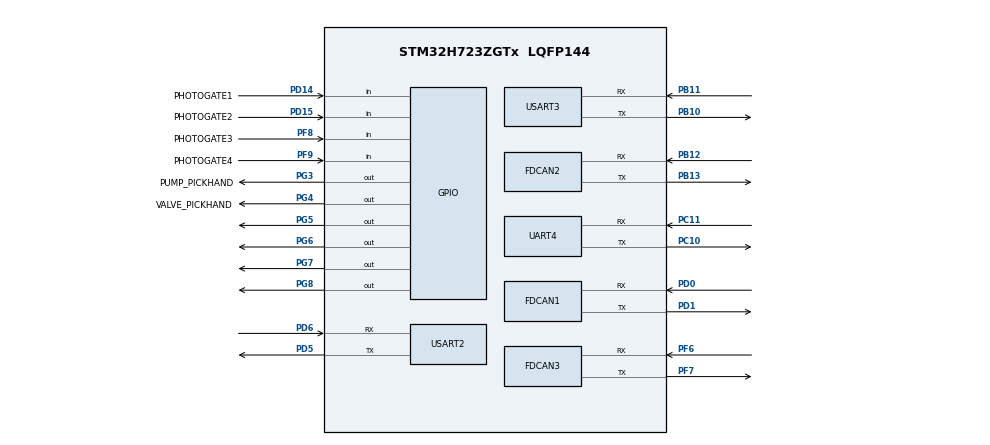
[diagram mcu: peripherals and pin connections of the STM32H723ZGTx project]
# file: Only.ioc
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CORTEX_M7.default_mode_Activation=1
Dma.Request0=USART3_TX
Dma.Request1=USART3_RX
Dma.Request2=USART2_RX
Dma.Request3=USART2_TX
Dma.Request4=UART4_RX
Dma.Request5=UART4_TX
Dma.UART4_RX.4.Direction=DMA_PERIPH_TO_MEMORY
Dma.UART4_RX.4.EventEnable=DISABLE
Dma.UART4_RX.4.FIFOMode=DMA_FIFOMODE_DISABLE
Dma.UART4_RX.4.Instance=DMA1_Stream4
Dma.UART4_RX.4.MemDataAlignment=DMA_MDATAALIGN_BYTE
Dma.UART4_RX.4.MemInc=DMA_MINC_ENABLE
Dma.UART4_RX.4.Mode=DMA_CIRCULAR
Dma.UART4_RX.4.PeriphDataAlignment=DMA_PDATAALIGN_BYTE
Dma.UART4_RX.4.PeriphInc=DMA_PINC_DISABLE
Dma.UART4_RX.4.Polarity=HAL_DMAMUX_REQ_GEN_RISING
Dma.UART4_RX.4.Priority=DMA_PRIORITY_LOW
Dma.UART4_RX.4.RequestNumber=1
Dma.UART4_RX.4.SignalID=NONE
Dma.UART4_RX.4.SyncEnable=DISABLE
Dma.UART4_RX.4.SyncPolarity=HAL_DMAMUX_SYNC_NO_EVENT
Dma.UART4_RX.4.SyncRequestNumber=1
Dma.UART4_RX.4.SyncSignalID=NONE
Dma.UART4_TX.5.Direction=DMA_MEMORY_TO_PERIPH
Dma.UART4_TX.5.EventEnable=DISABLE
Dma.UART4_TX.5.FIFOMode=DMA_FIFOMODE_DISABLE
Dma.UART4_TX.5.Instance=DMA1_Stream5
Dma.UART4_TX.5.MemDataAlignment=DMA_MDATAALIGN_BYTE
Dma.UART4_TX.5.MemInc=DMA_MINC_ENABLE
Dma.UART4_TX.5.Mode=DMA_NORMAL
Dma.UART4_TX.5.PeriphDataAlignment=DMA_PDATAALIGN_BYTE
Dma.UART4_TX.5.PeriphInc=DMA_PINC_DISABLE
Dma.UART4_TX.5.Polarity=HAL_DMAMUX_REQ_GEN_RISING
Dma.UART4_TX.5.Priority=DMA_PRIORITY_LOW
Dma.UART4_TX.5.RequestNumber=1
Dma.UART4_TX.5.SignalID=NONE
Dma.UART4_TX.5.SyncEnable=DISABLE
Dma.UART4_TX.5.SyncPolarity=HAL_DMAMUX_SYNC_NO_EVENT
Dma.UART4_TX.5.SyncRequestNumber=1
Dma.UART4_TX.5.SyncSignalID=NONE
Dma.USART2_RX.2.Direction=DMA_PERIPH_TO_MEMORY
Dma.USART2_RX.2.EventEnable=DISABLE
Dma.USART2_RX.2.FIFOMode=DMA_FIFOMODE_DISABLE
Dma.USART2_RX.2.Instance=DMA1_Stream2
Dma.USART2_RX.2.MemDataAlignment=DMA_MDATAALIGN_BYTE
Dma.USART2_RX.2.MemInc=DMA_MINC_ENABLE
Dma.USART2_RX.2.Mode=DMA_CIRCULAR
Dma.USART2_RX.2.PeriphDataAlignment=DMA_PDATAALIGN_BYTE
Dma.USART2_RX.2.PeriphInc=DMA_PINC_DISABLE
Dma.USART2_RX.2.Polarity=HAL_DMAMUX_REQ_GEN_RISING
Dma.USART2_RX.2.Priority=DMA_PRIORITY_LOW
Dma.USART2_RX.2.RequestNumber=1
Dma.USART2_RX.2.SignalID=NONE
Dma.USART2_RX.2.SyncEnable=DISABLE
Dma.USART2_RX.2.SyncPolarity=HAL_DMAMUX_SYNC_NO_EVENT
Dma.USART2_RX.2.SyncRequestNumber=1
Dma.USART2_RX.2.SyncSignalID=NONE
Dma.USART2_TX.3.Direction=DMA_MEMORY_TO_PERIPH
Dma.USART2_TX.3.EventEnable=DISABLE
Dma.USART2_TX.3.FIFOMode=DMA_FIFOMODE_DISABLE
Dma.USART2_TX.3.Instance=DMA1_Stream3
Dma.USART2_TX.3.MemDataAlignment=DMA_MDATAALIGN_BYTE
Dma.USART2_TX.3.MemInc=DMA_MINC_ENABLE
Dma.USART2_TX.3.Mode=DMA_NORMAL
Dma.USART2_TX.3.PeriphDataAlignment=DMA_PDATAALIGN_BYTE
Dma.USART2_TX.3.PeriphInc=DMA_PINC_DISABLE
Dma.USART2_TX.3.Polarity=HAL_DMAMUX_REQ_GEN_RISING
Dma.USART2_TX.3.Priority=DMA_PRIORITY_LOW
Dma.USART2_TX.3.RequestNumber=1
Dma.USART2_TX.3.SignalID=NONE
Dma.USART2_TX.3.SyncEnable=DISABLE
Dma.USART2_TX.3.SyncPolarity=HAL_DMAMUX_SYNC_NO_EVENT
Dma.USART2_TX.3.SyncRequestNumber=1
Dma.USART2_TX.3.SyncSignalID=NONE
Dma.USART3_RX.1.Direction=DMA_PERIPH_TO_MEMORY
Dma.USART3_RX.1.EventEnable=DISABLE
Dma.USART3_RX.1.FIFOMode=DMA_FIFOMODE_DISABLE
Dma.USART3_RX.1.Instance=DMA1_Stream1
Dma.USART3_RX.1.MemDataAlignment=DMA_MDATAALIGN_BYTE
Dma.USART3_RX.1.MemInc=DMA_MINC_ENABLE
Dma.USART3_RX.1.Mode=DMA_CIRCULAR
Dma.USART3_RX.1.PeriphDataAlignment=DMA_PDATAALIGN_BYTE
Dma.USART3_RX.1.PeriphInc=DMA_PINC_DISABLE
Dma.USART3_RX.1.Polarity=HAL_DMAMUX_REQ_GEN_RISING
Dma.USART3_RX.1.Priority=DMA_PRIORITY_LOW
Dma.USART3_RX.1.RequestNumber=1
Dma.USART3_RX.1.SignalID=NONE
Dma.USART3_RX.1.SyncEnable=DISABLE
Dma.USART3_RX.1.SyncPolarity=HAL_DMAMUX_SYNC_NO_EVENT
Dma.USART3_RX.1.SyncRequestNumber=1
Dma.USART3_RX.1.SyncSignalID=NONE
Dma.USART3_TX.0.Direction=DMA_MEMORY_TO_PERIPH
Dma.USART3_TX.0.EventEnable=DISABLE
Dma.USART3_TX.0.FIFOMode=DMA_FIFOMODE_DISABLE
Dma.USART3_TX.0.Instance=DMA1_Stream0
Dma.USART3_TX.0.MemDataAlignment=DMA_MDATAALIGN_BYTE
Dma.USART3_TX.0.MemInc=DMA_MINC_ENABLE
Dma.USART3_TX.0.Mode=DMA_NORMAL
Dma.USART3_TX.0.PeriphDataAlignment=DMA_PDATAALIGN_BYTE
Dma.USART3_TX.0.PeriphInc=DMA_PINC_DISABLE
Dma.USART3_TX.0.Polarity=HAL_DMAMUX_REQ_GEN_RISING
Dma.USART3_TX.0.Priority=DMA_PRIORITY_LOW
Dma.USART3_TX.0.RequestNumber=1
Dma.USART3_TX.0.SignalID=NONE
Dma.USART3_TX.0.SyncEnable=DISABLE
Dma.USART3_TX.0.SyncPolarity=HAL_DMAMUX_SYNC_NO_EVENT
Dma.USART3_TX.0.SyncRequestNumber=1
Dma.USART3_TX.0.SyncSignalID=NONE
FDCAN1.CalculateBaudRateNominal=1000000
FDCAN1.CalculateTimeBitNominal=1000
FDCAN1.CalculateTimeQuantumNominal=40.0
FDCAN1.DataSyncJumpWidth=2
FDCAN1.DataTimeSeg1=15
FDCAN1.DataTimeSeg2=9
FDCAN1.ExtFiltersNbr=2
FDCAN1.NominalPrescaler=1
FDCAN1.NominalSyncJumpWidth=2
FDCAN1.NominalTimeSeg1=15
FDCAN1.NominalTimeSeg2=9
FDCAN1.RxFifo0ElmtsNbr=8
FDCAN1.RxFifo1ElmtsNbr=8
FDCAN1.StdFiltersNbr=2
FDCAN1.TxBuffersNbr=29
FDCAN1.TxFifoQueueElmtsNbr=3
FDCAN2.CalculateBaudRateNominal=1000000
FDCAN2.CalculateTimeBitNominal=1000
FDCAN2.CalculateTimeQuantumNominal=40.0
FDCAN2.DataSyncJumpWidth=2
FDCAN2.DataTimeSeg1=15
FDCAN2.DataTimeSeg2=9
FDCAN2.ExtFiltersNbr=2
FDCAN2.MessageRAMOffset=0x400
FDCAN2.NominalPrescaler=1
FDCAN2.NominalSyncJumpWidth=2
FDCAN2.NominalTimeSeg1=15
FDCAN2.NominalTimeSeg2=9
FDCAN2.RxFifo0ElmtsNbr=8
FDCAN2.RxFifo1ElmtsNbr=8
FDCAN2.StdFiltersNbr=2
FDCAN2.TxBuffersNbr=0
FDCAN2.TxFifoQueueElmtsNbr=32
FDCAN3.CalculateBaudRateNominal=1000000
FDCAN3.CalculateTimeBitNominal=1000
FDCAN3.CalculateTimeQuantumNominal=40.0
FDCAN3.DataPrescaler=1
FDCAN3.DataSyncJumpWidth=2
FDCAN3.DataTimeSeg1=15
FDCAN3.DataTimeSeg2=9
FDCAN3.ExtFiltersNbr=2
FDCAN3.MessageRAMOffset=0x800
FDCAN3.NominalPrescaler=1
FDCAN3.NominalSyncJumpWidth=2
FDCAN3.NominalTimeSeg1=15
FDCAN3.NominalTimeSeg2=9
FDCAN3.RxFifo0ElmtsNbr=8
FDCAN3.RxFifo1ElmtsNbr=8
FDCAN3.StdFiltersNbr=2
FDCAN3.TxBuffersNbr=29
FDCAN3.TxFifoQueueElmtsNbr=3
FREERTOS.Tasks01=defaultTask,24,128,StartDefaultTask,Default,NULL,Dynamic,NULL,NULL
FREERTOS.configENABLE_FPU=1
Mcu.Family=STM32H7
Mcu.Name=STM32H723ZGTx
Mcu.Package=LQFP144
NVIC.DMA1_Stream0_IRQn=true\:5\:0\:false\:false\:true\:true\:false\:true\:true
NVIC.DMA1_Stream1_IRQn=true\:5\:0\:false\:false\:true\:true\:false\:true\:true
NVIC.DMA1_Stream2_IRQn=true\:5\:0\:false\:false\:true\:true\:false\:true\:true
NVIC.DMA1_Stream3_IRQn=true\:5\:0\:false\:false\:true\:true\:false\:true\:true
NVIC.DMA1_Stream4_IRQn=true\:5\:0\:false\:false\:true\:true\:false\:true\:true
NVIC.DMA1_Stream5_IRQn=true\:5\:0\:false\:false\:true\:true\:false\:true\:true
NVIC.FDCAN1_IT0_IRQn=true\:5\:0\:false\:false\:true\:true\:true\:true\:true
NVIC.FDCAN1_IT1_IRQn=true\:5\:0\:false\:false\:true\:true\:true\:true\:true
NVIC.FDCAN2_IT0_IRQn=true\:5\:0\:false\:false\:true\:true\:true\:true\:true
NVIC.FDCAN2_IT1_IRQn=true\:5\:0\:false\:false\:true\:true\:true\:true\:true
NVIC.FDCAN3_IT0_IRQn=true\:5\:0\:false\:false\:true\:true\:true\:true\:true
NVIC.FDCAN3_IT1_IRQn=true\:5\:0\:false\:false\:true\:true\:true\:true\:true
NVIC.PriorityGroup=NVIC_PRIORITYGROUP_4
NVIC.TIM6_DAC_IRQn=true\:15\:0\:false\:false\:true\:false\:false\:true\:true
NVIC.TimeBase=TIM6_DAC_IRQn
NVIC.TimeBaseIP=TIM6
NVIC.UART4_IRQn=true\:5\:0\:false\:false\:true\:true\:true\:true\:true
NVIC.USART2_IRQn=true\:5\:0\:false\:false\:true\:true\:true\:true\:true
NVIC.USART3_IRQn=true\:5\:0\:false\:false\:true\:true\:true\:true\:true
PB10.Mode=Asynchronous
PB10.Signal=USART3_TX
PB11.Mode=Asynchronous
PB11.Signal=USART3_RX
PB12.Mode=FDCAN_Activate
PB12.Signal=FDCAN2_RX
PB13.Mode=FDCAN_Activate
PB13.Signal=FDCAN2_TX
PC10.Mode=Asynchronous
PC10.Signal=UART4_TX
PC11.Mode=Asynchronous
PC11.Signal=UART4_RX
PD0.Mode=FDCAN_Activate
PD0.Signal=FDCAN1_RX
PD1.Mode=FDCAN_Activate
PD1.Signal=FDCAN1_TX
PD14.GPIO_Label=PHOTOGATE1
PD14.GPIO_PuPd=GPIO_PULLUP
PD14.Signal=GPIO_Input
PD15.GPIO_Label=PHOTOGATE2
PD15.GPIO_PuPd=GPIO_PULLUP
PD15.Signal=GPIO_Input
PD5.Mode=Asynchronous
PD5.Signal=USART2_TX
PD6.Mode=Asynchronous
PD6.Signal=USART2_RX
PF6.Mode=FDCAN_Activate
PF6.Signal=FDCAN3_RX
PF7.Mode=FDCAN_Activate
PF7.Signal=FDCAN3_TX
PF8.GPIO_Label=PHOTOGATE3
PF8.GPIO_PuPd=GPIO_PULLUP
PF8.Signal=GPIO_Input
PF9.GPIO_Label=PHOTOGATE4
PF9.GPIO_PuPd=GPIO_PULLUP
PF9.Signal=GPIO_Input
PG3.GPIO_Label=PUMP_PICKHAND
PG3.Signal=GPIO_Output
PG4.GPIO_Label=VALVE_PICKHAND
PG4.Signal=GPIO_Output
PG5.Signal=GPIO_Output
PG6.Signal=GPIO_Output
PG7.Signal=GPIO_Output
PG8.Signal=GPIO_Output
PH0-OSC_IN.Mode=HSE-External-Oscillator
PH0-OSC_IN.Signal=RCC_OSC_IN
PH1-OSC_OUT.Mode=HSE-External-Oscillator
PH1-OSC_OUT.Signal=RCC_OSC_OUT
ProjectManager.HeapSize=0x1000
ProjectManager.StackSize=0x1500
ProjectManager.TargetToolchain=CMake
RCC.ADCFreq_Value=50390625
RCC.APB1Freq_Value=137500000
RCC.APB2Freq_Value=137500000
RCC.APB3Freq_Value=137500000
RCC.APB4Freq_Value=137500000
RCC.CortexFreq_Value=550000000
RCC.D1PPRE=RCC_APB3_DIV2
RCC.D2PPRE1=RCC_APB1_DIV2
RCC.D2PPRE2=RCC_APB2_DIV2
RCC.D3PPRE=RCC_APB4_DIV2
RCC.DIVM1=2
RCC.DIVN1=44
RCC.DIVP1=1
RCC.DIVQ1=4
RCC.FDCANCLockSelection=RCC_FDCANCLKSOURCE_HSE
RCC.HCLKFreq_Value=275000000
RCC.HPRE=RCC_HCLK_DIV2
RCC.PLLFRACN=0
RCC.PLLSourceVirtual=RCC_PLLSOURCE_HSE
RCC.SYSCLKFreq_VALUE=550000000
RCC.SYSCLKSource=RCC_SYSCLKSOURCE_PLLCLK
RCC.USBFreq_Value=137500000
USART2.VirtualMode-Asynchronous=VM_ASYNC
USART3.VirtualMode-Asynchronous=VM_ASYNC
VP_FREERTOS_VS_CMSIS_V2.Mode=CMSIS_V2
VP_MEMORYMAP_VS_MEMORYMAP.Mode=CurAppReg
VP_SYS_VS_tim6.Mode=TIM6
board=custom

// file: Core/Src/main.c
/* USER CODE BEGIN Header */
/**
  ******************************************************************************
  * @file           : main.c
  * @brief          : Main program body
  ******************************************************************************
  * @attention
  *
  * Copyright (c) 2026 STMicroelectronics.
  * All rights reserved.
  *
  * This software is licensed under terms that can be found in the LICENSE file
  * in the root directory of this software component.
  * If no LICENSE file comes with this software, it is provided AS-IS.
  *
  ******************************************************************************
  */
/* USER CODE END Header */
#include "main.h"
#include "FreeRTOS.h"
#include "cmsis_os2.h"
#include "dma.h"
#include "fdcan.h"
#include "usart.h"
#include "gpio.h"

/* USER CODE BEGIN Includes */
#include "robot_task.h"
#include "robot.h"
/* USER CODE END Includes */

void SystemClock_Config(void);
static void MPU_Config(void);
void MX_FREERTOS_Init(void);

int main(void)
{

  /* MPU Configuration--------------------------------------------------------*/
  MPU_Config();

  /* MCU Configuration--------------------------------------------------------*/

  /* Reset of all peripherals, Initializes the Flash interface and the Systick. */
  HAL_Init();

  /* Configure the system clock */
  SystemClock_Config();

  /* Initialize all configured peripherals */
  MX_GPIO_Init();
  MX_DMA_Init();
  MX_USART3_UART_Init();
  MX_USART2_UART_Init();
  MX_FDCAN1_Init();
  MX_FDCAN2_Init();
  MX_FDCAN3_Init();
  MX_UART4_Init();
  /* USER CODE BEGIN 2 */
  Robot_Init();
  /* USER CODE END 2 */

  /* Init scheduler */
  osKernelInitialize();  /* Call init function for freertos objects (in cmsis_os2.c) */
  MX_FREERTOS_Init();

  /* Start scheduler */
  osKernelStart();

  /* We should never get here as control is now taken by the scheduler */

  /* Infinite loop */
  while (1)
  {

  }
}

void SystemClock_Config(void)
{
  RCC_OscInitTypeDef RCC_OscInitStruct = {0};
  RCC_ClkInitTypeDef RCC_ClkInitStruct = {0};

  /** Supply configuration update enable
  */
  HAL_PWREx_ConfigSupply(PWR_LDO_SUPPLY);

  /** Configure the main internal regulator output voltage
  */
  __HAL_PWR_VOLTAGESCALING_CONFIG(PWR_REGULATOR_VOLTAGE_SCALE0);

  while(!__HAL_PWR_GET_FLAG(PWR_FLAG_VOSRDY)) {}

  /** Initializes the RCC Oscillators according to the specified parameters
  * in the RCC_OscInitTypeDef structure.
  */
  RCC_OscInitStruct.OscillatorType = RCC_OSCILLATORTYPE_HSE;
  RCC_OscInitStruct.HSEState = RCC_HSE_ON;
  RCC_OscInitStruct.PLL.PLLState = RCC_PLL_ON;
  RCC_OscInitStruct.PLL.PLLSource = RCC_PLLSOURCE_HSE;
  RCC_OscInitStruct.PLL.PLLM = 2;
  RCC_OscInitStruct.PLL.PLLN = 44;
  RCC_OscInitStruct.PLL.PLLP = 1;
  RCC_OscInitStruct.PLL.PLLQ = 4;
  RCC_OscInitStruct.PLL.PLLR = 2;
  RCC_OscInitStruct.PLL.PLLRGE = RCC_PLL1VCIRANGE_3;
  RCC_OscInitStruct.PLL.PLLVCOSEL = RCC_PLL1VCOWIDE;
  RCC_OscInitStruct.PLL.PLLFRACN = 0;
  if (HAL_RCC_OscConfig(&RCC_OscInitStruct) != HAL_OK)
  {
    Error_Handler();
  }

  /** Initializes the CPU, AHB and APB buses clocks
  */
  RCC_ClkInitStruct.ClockType = RCC_CLOCKTYPE_HCLK|RCC_CLOCKTYPE_SYSCLK
                              |RCC_CLOCKTYPE_PCLK1|RCC_CLOCKTYPE_PCLK2
                              |RCC_CLOCKTYPE_D3PCLK1|RCC_CLOCKTYPE_D1PCLK1;
  RCC_ClkInitStruct.SYSCLKSource = RCC_SYSCLKSOURCE_PLLCLK;
  RCC_ClkInitStruct.SYSCLKDivider = RCC_SYSCLK_DIV1;
  RCC_ClkInitStruct.AHBCLKDivider = RCC_HCLK_DIV2;
  RCC_ClkInitStruct.APB3CLKDivider = RCC_APB3_DIV2;
  RCC_ClkInitStruct.APB1CLKDivider = RCC_APB1_DIV2;
  RCC_ClkInitStruct.APB2CLKDivider = RCC_APB2_DIV2;
  RCC_ClkInitStruct.APB4CLKDivider = RCC_APB4_DIV2;

  if (HAL_RCC_ClockConfig(&RCC_ClkInitStruct, FLASH_LATENCY_3) != HAL_OK)
  {
    Error_Handler();
  }
}

 /* MPU Configuration */

void MPU_Config(void)
{
  MPU_Region_InitTypeDef MPU_InitStruct = {0};

  /* Disables the MPU */
  HAL_MPU_Disable();

  /** Initializes and configures the Region and the memory to be protected
  */
  MPU_InitStruct.Enable = MPU_REGION_ENABLE;
  MPU_InitStruct.Number = MPU_REGION_NUMBER0;
  MPU_InitStruct.BaseAddress = 0x0;
  MPU_InitStruct.Size = MPU_REGION_SIZE_4GB;
  MPU_InitStruct.SubRegionDisable = 0x87;
  MPU_InitStruct.TypeExtField = MPU_TEX_LEVEL0;
  MPU_InitStruct.AccessPermission = MPU_REGION_NO_ACCESS;
  MPU_InitStruct.DisableExec = MPU_INSTRUCTION_ACCESS_DISABLE;
  MPU_InitStruct.IsShareable = MPU_ACCESS_SHAREABLE;
  MPU_InitStruct.IsCacheable = MPU_ACCESS_NOT_CACHEABLE;
  MPU_InitStruct.IsBufferable = MPU_ACCESS_NOT_BUFFERABLE;

  HAL_MPU_ConfigRegion(&MPU_InitStruct);
  /* Enables the MPU */
  HAL_MPU_Enable(MPU_PRIVILEGED_DEFAULT);

}

void HAL_TIM_PeriodElapsedCallback(TIM_HandleTypeDef *htim)
{
  if (htim->Instance == TIM6)
  {
    HAL_IncTick();
  }
}

void Error_Handler(void)
{
  __disable_irq();
  while (1)
  {
  }
}
